# STM32L162xD register map
File version: 1.0
Registers are 32-bit, read-write, reset 0x0 unless marked. A register's access mark holds for its fields unless they carry their own. Offsets are from the block's base; [hi:lo] are bit positions; {n}, {i} and the like mark numbered series.

## EXTI — External Interrupt/Event Controller
Base 0x40010400
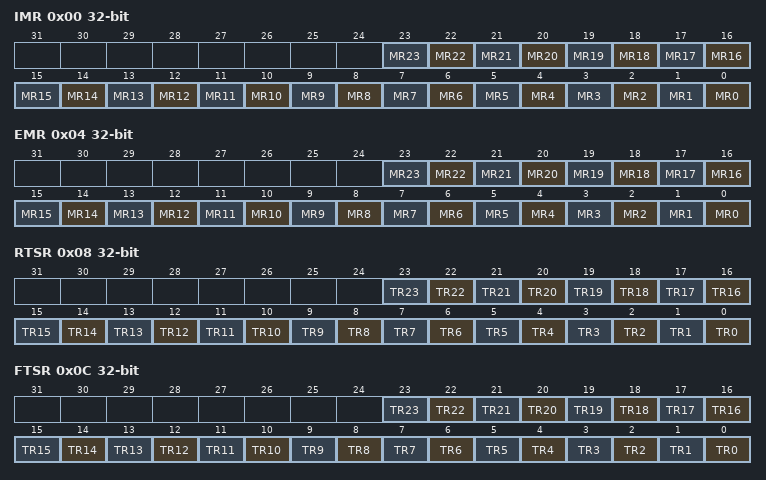
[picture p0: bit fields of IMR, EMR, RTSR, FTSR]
0x00 IMR — EXTI Interrupt mask register
  [n] MR{n} (n=0..23) — Interrupt Mask on line {n}
0x04 EMR — EXTI Event mask register
  [n] MR{n} (n=0..23) — Event Mask on line {n}
0x08 RTSR — EXTI Rising trigger selection register
  [n] TR{n} (n=0..23) — Rising trigger event configuration bit of line {n}
0x0C FTSR — EXTI Falling trigger selection register
  [n] TR{n} (n=0..23) — Falling trigger event configuration bit of line {n}
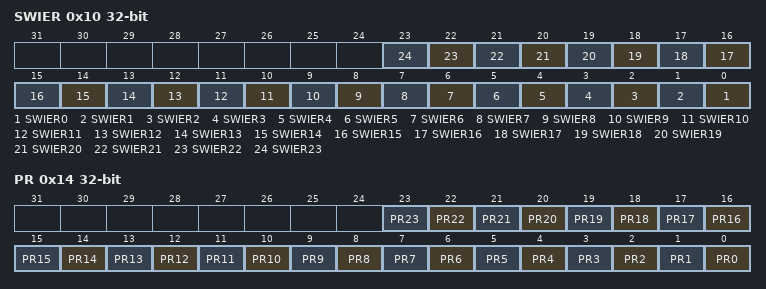
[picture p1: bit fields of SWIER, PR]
0x10 SWIER — EXTI Software interrupt event register
  [n] SWIER{n} (n=0..23) — Software Interrupt on line {n}
0x14 PR — EXTI Pending register
  [n] PR{n} (n=0..23) — Pending bit for line {n}

## GPIOA — General Purpose IO
Base 0x40020000
Same registers: GPIOB 0x40020400, GPIOC 0x40020800, GPIOD 0x40020C00, GPIOE 0x40021000, GPIOH 0x40021400, GPIOF 0x40021800, GPIOG 0x40021C00
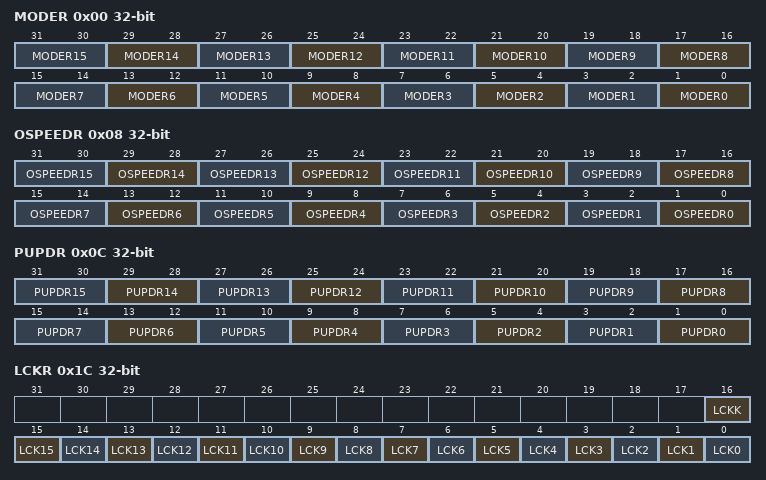
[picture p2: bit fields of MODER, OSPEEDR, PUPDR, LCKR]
0x00 MODER — GPIO port mode register
  [2n+1:2n] MODER{n} (n=0..15)
0x04 OTYPER — GPIO port output type register
0x08 OSPEEDR — GPIO port output speed register
  [2n+1:2n] OSPEEDR{n} (n=0..15)
0x0C PUPDR — GPIO port pull-up/pull-down register
  [2n+1:2n] PUPDR{n} (n=0..15)
0x10 IDR — GPIO port input data register
0x14 ODR — GPIO port output data register
0x18 BSRR — GPIO port bit set/reset registerBSRR
0x1C LCKR — GPIO port configuration lock register
  [16] LCKK, [n] LCK{n} (n=0..15)
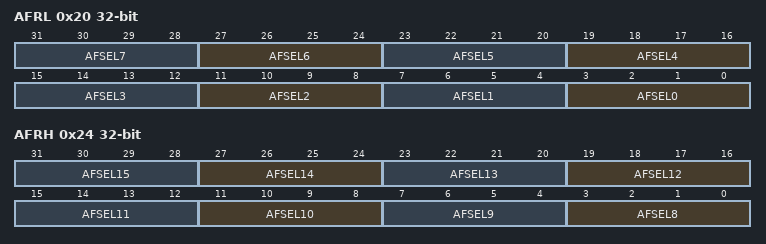
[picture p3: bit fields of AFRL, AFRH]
0x20 AFRL — GPIO alternate function register
  [4n+3:4n] AFSEL{n} (n=0..7)
0x24 AFRH — GPIO alternate function register
  [4n-29:4n-32] AFSEL{n} (n=8..15)
0x28 BRR — GPIO bit reset register

## CRC — CRC calculation unit
Base 0x40023000
0x00 DR — CRC Data register
  [31:0] DR — Data register bits
0x04 IDR 8-bit — CRC Independent data register
  [7:0] IDR — General-purpose 8-bit data register bits
0x08 CR — CRC Control register
  [0] RESET — RESET bit

## FLASH — FLASH Registers
Base 0x40023C00
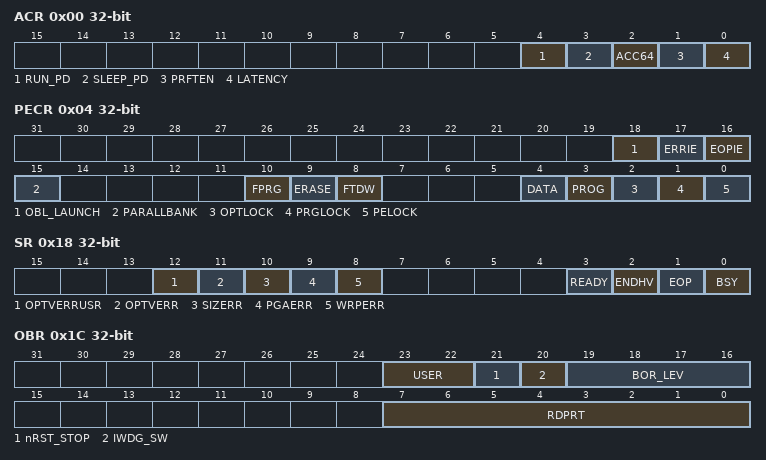
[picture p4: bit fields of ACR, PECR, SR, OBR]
0x00 ACR — Access control register
  [4] RUN_PD — Flash mode during RUN mode
  [3] SLEEP_PD — Flash mode during sleep mode
  [2] ACC64 — Access 64 bits
  [1] PRFTEN — Prefetch Buffer Enable
  [0] LATENCY
    0=FLASH Zero Latency cycle; 1=FLASH One Latency cycle
0x04 PECR — Program/erase control register
  [18] OBL_LAUNCH — Launch the option byte loading
  [17] ERRIE — Error interrupt
  [16] EOPIE — End of programming interrupt
  [15] PARALLBANK — Parallel Bank mode
  [10] FPRG — Fast Page/Half Page programming mode
  [9] ERASE — Page erasing mode
  [8] FTDW — Fixed Time Data write for Word/Half Word/Byte programming
  [4] DATA — Data matrix selection
  [3] PROG — Program matrix selection
  [2] OPTLOCK — Option byte matrix Lock
  [1] PRGLOCK — Program matrix Lock
  [0] PELOCK — FLASH_PECR and Flash data Lock
0x08 PDKEYR — Power down key register
  [31:0] PDKEYR — FLASH_PEC and data matrix Key
0x0C PEKEYR — Program/erase key register
  [31:0] PEKEYR — FLASH_PEC and data matrix Key
0x10 PRGKEYR — Program memory key register
  [31:0] PRGKEYR — Program matrix Key
0x14 OPTKEYR — Option byte key register
  [31:0] OPTKEYR — Option bytes matrix Key
0x18 SR — Status register
  [12] OPTVERRUSR — Option User validity error
  [11] OPTVERR — Option validity error
  [10] SIZERR — Size error
  [9] PGAERR — Programming Alignment Error
  [8] WRPERR — Write protected error
  [3] READY — Flash ready after low power mode
  [2] ENDHV — End of high voltage
  [1] EOP — End Of Programming
  [0] BSY — Busy
0x1C OBR — Option byte register
  [23:22] USER — User Option Bytes
  [21] nRST_STOP
  [20] IWDG_SW
  [19:16] BOR_LEV — BOR_LEV[3:0] Brown Out Reset Threshold Level
  [7:0] RDPRT — Read Protection
0x20 WRPR1 — Write protection register 1
  [31:0] WRP — Write Protect sectors 0 to 31
0x80 WRPR2 — Write protection register 2
  [31:0] WRP — Write Protect sectors 32 to 63
0x84 WRPR3 — Write protection register 3
  [31:0] WRP — Write Protect sectors 64 to 95
